# MDR1986VE81 register map
Vendor: Milandr; Series: ARMCM4; File version: 2.0
CPU: CM4 r0p0, little endian, MPU, FPU, 3 interrupt priority bits
Registers are 32-bit, read-write, reset 0x0 unless marked. A register's access mark holds for its fields unless they carry their own. Offsets are from the block's base; [hi:lo] are bit positions; {n}, {i} and the like mark numbered series; 'fields as' and 'values as' point back to an identical list.

## MDR_BKP — Backup and RTC Control
Base 0x40001000
{0x0+4i} REG[{i}] (i=0..59) — User backup registers
0xF0 KEY — Unlock BKP and RTC Registers
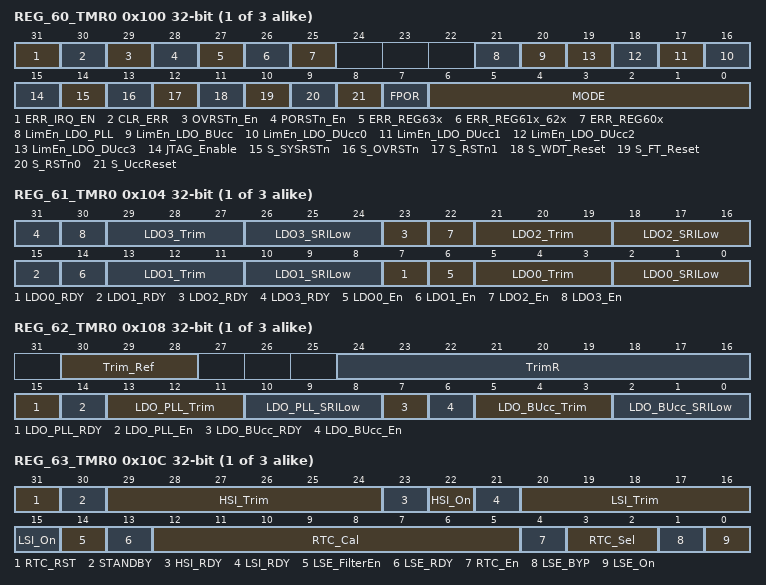
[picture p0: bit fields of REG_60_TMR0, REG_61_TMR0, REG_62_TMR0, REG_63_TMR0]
{0x100+0x10*i} REG_60_TMR{i} (i=0..2) — REG60 Control register
  [31] ERR_IRQ_EN — Enable BKP_IRQn on Errors
    0=Off (Disable); 1=On (Enable)
  [30] CLR_ERR — Clear Errors of REG_60x - 63x
    0=Inactive (Disable); 1=Clear Errors
  [29] OVRSTn_En — Enable reset by Ucc > U_over (5.75V)
    0=On (Enabled); 1=Off (Disabled)
  [28] PORSTn_En — Enable reset by Ucc > U_POR (2.5V)
    0=On (Enabled); 1=Off (Disabled)
  [27] ERR_REG63x — Fault in REG_63x
    0=Off (Event Inactive); 1=On (Event Active)
  [26] ERR_REG61x_62x — Fault in REG_61x or REG_62x
    0=Off (Event Inactive); 1=On (Event Active)
  [25] ERR_REG60x — Fault in REG_60x
    0=Off (Event Inactive); 1=On (Event Active)
  [21] LimEn_LDO_PLL — Enable limit for DUcc_PLL (~50mA)
    0=Off (Disable); 1=On (Enable)
  [20] LimEn_LDO_BUcc — Enable limit for DUcc_Bat (~50mA)
    0=Off (Disable); 1=On (Enable)
  [n+16] LimEn_LDO_DUcc{n} (n=0..3) — Enable limit for DUcc{n} (~300mA)
    0=Off (Disable); 1=On (Enable)
  [15] JTAG_Enable — Disable JTAG
    0=On (Enabled); 1=Off (Disabled)
  [14] S_SYSRSTn — Reset by software
    0=Off (Event Inactive); 1=On (Event Active)
  [13] S_OVRSTn — Reset by Ucc > U_over (5.75V)
    0=Off (Event Inactive); 1=On (Event Active)
  [12] S_RSTn1 — Reset by RSTn1 signal
    0=Off (Event Inactive); 1=On (Event Active)
  [11] S_WDT_Reset — Reset from WDT
    0=Off (Event Inactive); 1=On (Event Active)
  [10] S_FT_Reset — Reset from FT_CNTR
    0=Off (Event Inactive); 1=On (Event Active)
  [9] S_RSTn0 — Reset by RSTn0 signal
    0=Off (Event Inactive); 1=On (Event Active)
  [8] S_UccReset — Reset by Ucc
    0=Off (Event Inactive); 1=On (Event Active)
  [7] FPOR — Bootloader completed
    0=Bootloader active; 1=Completed (Bootloader completed)
  [6:0] MODE — Boot Mode
{0x104+0x10*i} REG_61_TMR{i} (i=0..2) — REG61 Control register
  [8n+7] LDO{n}_RDY (n=0..3) — LDO Ready
    0=NotReady (DUcc not ready); 1=Ready (DUcc ready)
  [8n+6] LDO{n}_En (n=0..3) — LDO Enable
    0=On (Enable); 1=Off (Disable)
  [8n+5:8n+3] LDO{n}_Trim (n=0..3) — LDO voltage tuning
    0=add_0v01 (LD0 extra voltage +0.01V); 1=add_0v05 (LD0 extra voltage +0.05V); 2=add_0v1 (LD0 extra voltage +0.1V); 3=add_0v15 (LD0 extra voltage +0.15V); 4=sub_0v01 (LD0 extra voltage -0.01V); 5=sub_0v05 (LD0 extra voltage -0.05V); 6=sub_0v015 (LD0 extra voltage -0.10V); 7=sub_0v15 (LD0 extra voltage -0.15V)
  [8n+2:8n] LDO{n}_SRILow (n=0..3) — LDO Power adjustment
    0=ge10MHz (Extra_I about ~400uA); 1=ge30MHz (Extra_I about ~450uA); 2=ge50MHz (Extra_I about ~550uA); 3=ge100MHz (Extra_I about ~650uA); 4=ge1MHz (Extra_I about ~300uA); 5=ge500KHz (Extra_I about ~200uA); 6=ge100KHz (Extra_I about ~100uA); 7=ge10KHz (Extra_I about ~50uA)
{0x108+0x10*i} REG_62_TMR{i} (i=0..2) — REG62 Control register
  [30:28] Trim_Ref ro — Do not change
    {v}=Tr{v} (Trim) (v=0..7)
  [24:16] TrimR ro — Do not change
  [15] LDO_PLL_RDY — LDO Ready
    0=NotReady (DUcc not ready); 1=Ready (DUcc ready)
  [14] LDO_PLL_En — LDO Enable
    0=On (Enable); 1=Off (Disable)
  [13:11] LDO_PLL_Trim — LDO voltage tuning
    values as REG_61_TMR0.LDO0_Trim
  [10:8] LDO_PLL_SRILow — LDO Power adjustment
    values as REG_61_TMR0.LDO0_SRILow
  [7] LDO_BUcc_RDY — LDO Ready
    0=NotReady (DUcc not ready); 1=Ready (DUcc ready)
  [6] LDO_BUcc_En — LDO Enable
    0=On (Enable); 1=Off (Disable)
  [5:3] LDO_BUcc_Trim — LDO voltage tuning
    values as REG_61_TMR0.LDO0_Trim
  [2:0] LDO_BUcc_SRILow — LDO Power adjustment
    values as REG_61_TMR0.LDO0_SRILow
{0x10C+0x10*i} REG_63_TMR{i} (i=0..2) — REG63 Control register
  [31] RTC_RST — RTC Reset
    0=Off (Disable); 1=On (Enable)
  [30] STANDBY — Go Standby mode
    0=Inactive (No Action); 1=GoStandby (Standby power off)
  [29:24] HSI_Trim — HSI trim freq
  [23] HSI_RDY — HSI Ready
    0=Off (Disable); 1=On (Enable)
  [22] HSI_On — HSI Enable
    0=Off (Disable); 1=On (Enable)
  [21] LSI_RDY — LSI Ready
    0=Off (Disable); 1=On (Enable)
  [20:16] LSI_Trim — LSI Trim freq
    0=Max8 (LSI Trim); 1=Max7 (LSI Trim); 2=Max6 (LSI Trim); 3=Max5 (LSI Trim); 4=Max4 (LSI Trim); 5=Max3 (LSI Trim); 6=Max2 (LSI Trim); 7=Max1 (LSI Trim); 8=Typical (LSI Default); {v}=Min{v-8} (LSI Trim) (v=9..15)
  [15] LSI_On — LSI Enable
    0=Off (Disable); 1=On (Enable)
  [14] LSE_FilterEn — LSE Filter Enable
    0=Off (Disable); 1=On (Enable)
  [13] LSE_RDY — LSE Ready
    0=Off (Disable); 1=On (Enable)
  [12:5] RTC_Cal — RTC pass counts
  [4] RTC_En — RTC Enable
    0=Off (Disable); 1=On (Enable)
  [3:2] RTC_Sel — Select Clock for RTC
    0=LSI (LSI Clock); 1=LSE (LSE Clock); 2=RTCCLK (RTCCLK Clock)
  [1] LSE_BYP — LSE Bypass
    0=Off (Disable); 1=On (Enable)
  [0] LSE_On — LSE Enable
    0=Off (Disable); 1=On (Enable)
{0x130+0x20*i} RTC_CNT_TMR{i} (i=0..2) — Count periods of PRL
{0x134+0x20*i} RTC_DIV_TMR{i} (i=0..2) — Counts RTC Clock to get PRL value
  [19:0] Value — RTC DIV value
{0x138+0x20*i} RTC_PRL_TMR{i} (i=0..2) — Period value for DIV counter
  [19:0] Value — RTC PRL value
{0x13C+0x20*i} RTC_ALRM_TMR{i} (i=0..2) — Event value for CNT counter
  [31:0] Value — Alarm value of CNT
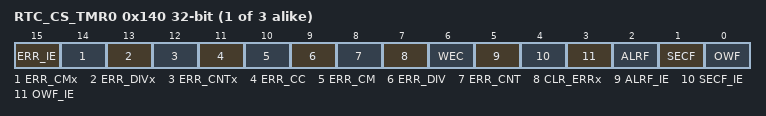
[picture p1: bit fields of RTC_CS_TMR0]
{0x140+0x20*i} RTC_CS_TMR{i} (i=0..2) — RTC Control and Status
  [15] ERR_IE — Enable IRQ on RTC faults
    0=Off (Disable); 1=On (Enable)
  [14] ERR_CMx — Self channel clock fault
    0=Off (No event); 1=On (Event Active)
  [13] ERR_DIVx — Self channel DIV fault
    0=Off (No event); 1=On (Event Active)
  [12] ERR_CNTx — Self channel CNT fault
    0=Off (No event); 1=On (Event Active)
  [11] ERR_CC — Clock RTC too low
    0=Off (No event); 1=On (Event Active)
  [10] ERR_CM — Clock RTC too high
    0=Off (No event); 1=On (Event Active)
  [9] ERR_DIV — DIVx mistmatches
    0=Off (No event); 1=On (Event Active)
  [8] ERR_CNT — CNTx mistmatches
    0=Off (No event); 1=On (Event Active)
  [7] CLR_ERRx — Clear Errors
    0=Inactive (No Action); 1=Clear ERR_x Errors
  [6] WEC — RTC Busy flag
    0=Ready (Registers available); 1=Busy (Registers unavailable)
  [5] ALRF_IE — Enable IRQ by ALRF
    0=Off (No Event); 1=On (Event)
  [4] SECF_IE — Enable IRQ by SECF
    0=Off (No Event); 1=On (Event)
  [3] OWF_IE — Enable IRQ by OWF
    0=Off (No Event); 1=On (Event)
  [2] ALRF — CNT == ALRM Event, clear by set 1
    0=Off (No Event); 1=On (Event)
  [1] SECF — DIV == PRL Event, clear by set 1
    0=Off (No Event); 1=On (Event)
  [0] OWF — CNT Overflow flag, clear by set 1
    0=Off (No Event); 1=On (Event)
